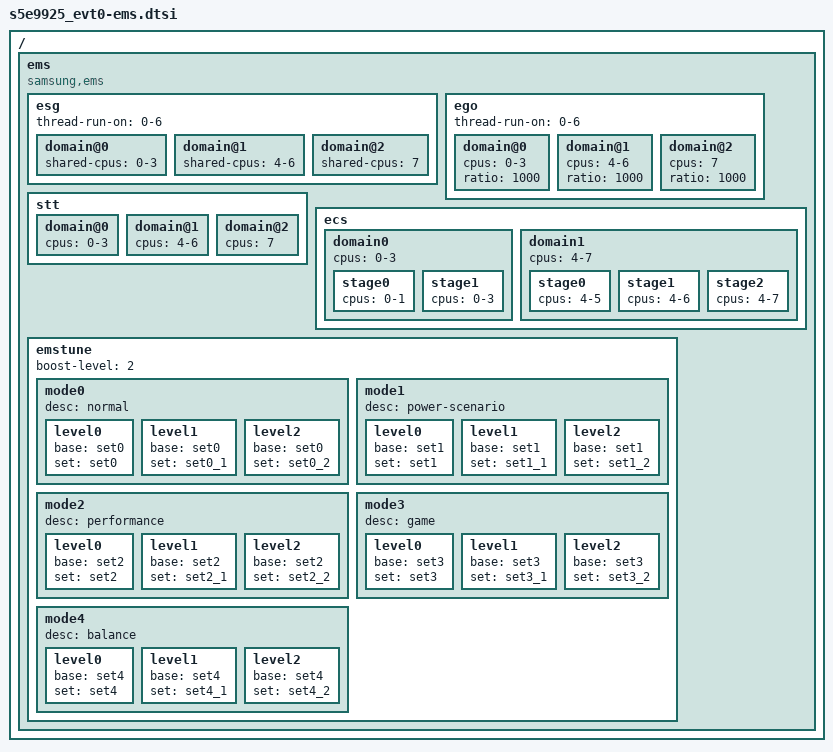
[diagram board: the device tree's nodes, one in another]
/*
 * SAMSUNG EXYNOS SoC EMS device tree source
 *
 * Copyright (c) 2019 Samsung Electronics Co., Ltd.
 *             http://www.samsung.com
 *
 * SAMSUNG EXYNOS SoC EMS device nodes are listed in this file.
 * EXYNOS based board files should include this file.
 *
 * This program is free software; you can redistribute it and/or modify
 * it under the terms of the GNU General Public License version 2 as
 * published by the Free Software Foundation.
 *
 */
#include <dt-bindings/soc/samsung/ems.h>

#include "emstune/s5e9925/sets.dtsi"

/ {
	ems {
		compatible = "samsung,ems";
		status = "okay";

		esg {
			thread-run-on = "0-6";

			domain@0 {
				shared-cpus = "0-3";
			};
			domain@1 {
				shared-cpus = "4-6";
			};
			domain@2 {
				shared-cpus = "7";
			};
		};

		ego {
			thread-run-on = "0-6";

			domain@0 {
				cpus = "0-3";
				ratio = < 1000 >;
			};
			domain@1 {
				cpus = "4-6";
				ratio = < 1000 >;
			};
			domain@2 {
				cpus = "7";
				ratio = < 1000 >;
			};
		};

		stt {
			domain@0 {
				cpus = "0-3";
			};
			domain@1 {
				cpus = "4-6";
			};
			domain@2 {
				cpus = "7";
			};
		};

		ecs {
			domain0 {
				cpus = "0-3";

				stage0 {
					cpus = "0-1";
				};
				stage1 {
					cpus = "0-3";
				};
			};
			domain1 {
				cpus = "4-7";

				stage0 {
					cpus = "4-5";
				};
				stage1 {
					cpus = "4-6";
				};
				stage2 {
					cpus = "4-7";
				};
			};
		};

		emstune {
			boost-level = <2>;

			mode0 {
				desc = "normal";

				level0 {
					base = <&set0>;
					set = <&set0>;
				};
				level1 {
					base = <&set0>;
					set = <&set0_1>;
				};
				level2 {
					base = <&set0>;
					set = <&set0_2>;
				};
			};
			mode1 {
				desc = "power-scenario";

				level0 {
					base = <&set1>;
					set = <&set1>;
				};
				level1 {
					base = <&set1>;
					set = <&set1_1>;
				};
				level2 {
					base = <&set1>;
					set = <&set1_2>;
				};
			};
			mode2 {
				desc = "performance";

				level0 {
					base = <&set2>;
					set = <&set2>;
				};
				level1 {
					base = <&set2>;
					set = <&set2_1>;
				};
				level2 {
					base = <&set2>;
					set = <&set2_2>;
				};
			};
			mode3 {
				desc = "game";

				level0 {
					base = <&set3>;
					set = <&set3>;
				};
				level1 {
					base = <&set3>;
					set = <&set3_1>;
				};
				level2 {
					base = <&set3>;
					set = <&set3_2>;
				};
			};
			mode4 {
				desc = "balance";

				level0 {
					base = <&set4>;
					set = <&set4>;
				};
				level1 {
					base = <&set4>;
					set = <&set4_1>;
				};
				level2 {
					base = <&set4>;
					set = <&set4_2>;
				};
			};
		};
	};
};
